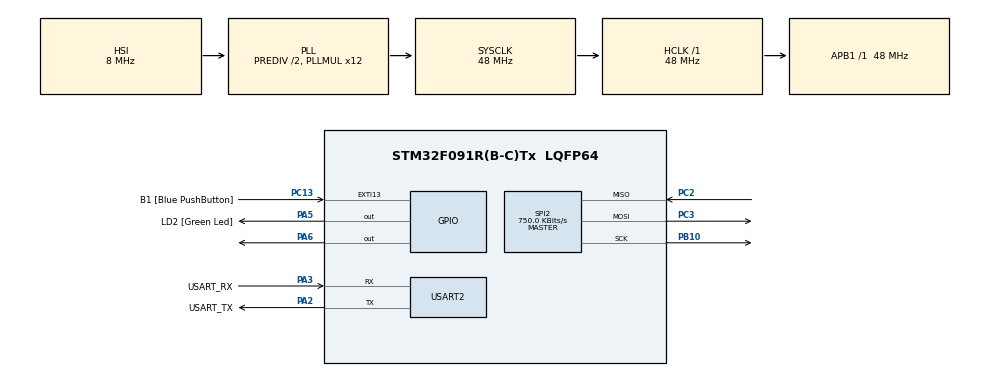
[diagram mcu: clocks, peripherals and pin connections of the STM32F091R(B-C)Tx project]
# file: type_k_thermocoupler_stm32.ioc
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Mcu.Family=STM32F0
Mcu.Name=STM32F091R(B-C)Tx
Mcu.Package=LQFP64
PA13.GPIO_Label=TMS
PA13.Mode=Serial_Wire
PA13.Signal=SYS_SWDIO
PA14.GPIO_Label=TCK
PA14.Mode=Serial_Wire
PA14.Signal=SYS_SWCLK
PA2.GPIO_Label=USART_TX
PA2.GPIO_Mode=GPIO_MODE_AF_PP
PA2.GPIO_PuPd=GPIO_NOPULL
PA2.GPIO_Speed=GPIO_SPEED_FREQ_LOW
PA2.Mode=Asynchronous
PA2.Signal=USART2_TX
PA3.GPIO_Label=USART_RX
PA3.GPIO_Mode=GPIO_MODE_AF_PP
PA3.GPIO_PuPd=GPIO_NOPULL
PA3.GPIO_Speed=GPIO_SPEED_FREQ_LOW
PA3.Mode=Asynchronous
PA3.Signal=USART2_RX
PA5.GPIO_Label=LD2 [Green Led]
PA5.GPIO_Mode=GPIO_MODE_OUTPUT_PP
PA5.GPIO_PuPd=GPIO_NOPULL
PA5.GPIO_Speed=GPIO_SPEED_FREQ_LOW
PA5.Signal=GPIO_Output
PA6.Signal=GPIO_Output
PB10.Mode=Full_Duplex_Master
PB10.Signal=SPI2_SCK
PC13.GPIO_Label=B1 [Blue PushButton]
PC13.GPIO_ModeDefaultEXTI=GPIO_MODE_IT_FALLING
PC13.Signal=GPXTI13
PC14OSC32_IN.Mode=LSE-External-Oscillator
PC14OSC32_IN.Signal=RCC_OSC32_IN
PC15OSC32_OUT.Mode=LSE-External-Oscillator
PC15OSC32_OUT.Signal=RCC_OSC32_OUT
PC2.Mode=Full_Duplex_Master
PC2.Signal=SPI2_MISO
PC3.Mode=Full_Duplex_Master
PC3.Signal=SPI2_MOSI
PF0-OSC_IN.Mode=HSE-External-Clock-Source
PF0-OSC_IN.Signal=RCC_OSC_IN
PF1-OSC_OUT.Signal=RCC_OSC_OUT
ProjectManager.HeapSize=0x200
ProjectManager.StackSize=0x400
ProjectManager.TargetToolchain=STM32CubeIDE
RCC.AHBFreq_Value=48000000
RCC.APB1Freq_Value=48000000
RCC.APB1TimFreq_Value=48000000
RCC.FLatency-AdvancedSettings=FLASH_LATENCY_1
RCC.HCLKFreq_Value=48000000
RCC.PLLDivider=RCC_PREDIV_DIV2
RCC.PLLMUL=RCC_PLL_MUL12
RCC.PREFETCH_ENABLE-AdvancedSettings=1
RCC.SYSCLKFreq_VALUE=48000000
RCC.SYSCLKSource=RCC_SYSCLKSOURCE_PLLCLK
SPI2.BaudRatePrescaler=SPI_BAUDRATEPRESCALER_64
SPI2.CalculateBaudRate=750.0 KBits/s
SPI2.DataSize=SPI_DATASIZE_16BIT
SPI2.Direction=SPI_DIRECTION_2LINES
SPI2.Mode=SPI_MODE_MASTER
SPI2.VirtualType=VM_MASTER
USART2.VirtualMode=VM_ASYNC
USART2.VirtualMode-Asynchronous=VM_ASYNC
board=NUCLEO-F091RC

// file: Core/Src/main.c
/* USER CODE BEGIN Header */
/**
  ******************************************************************************
  * @file           : main.c
  * @brief          : Main program body
  ******************************************************************************
  * @attention
  *
  * Copyright (c) 2022 STMicroelectronics.
  * All rights reserved.
  *
  * This software is licensed under terms that can be found in the LICENSE file
  * in the root directory of this software component.
  * If no LICENSE file comes with this software, it is provided AS-IS.
  *
  ******************************************************************************
  */
/* USER CODE END Header */
#include "main.h"

#include <stdio.h>
#include <string.h>
#include "max6675.h"

SPI_HandleTypeDef hspi2;
ThermoCouple sensor_th1;
UART_HandleTypeDef huart2;

void SystemClock_Config(void);
static void MX_GPIO_Init(void);
static void MX_USART2_UART_Init(void);
static void MX_SPI2_Init(void);
static void InitThermocouple1(void);

int main(void)
{

  /* MCU Configuration--------------------------------------------------------*/

  /* Reset of all peripherals, Initializes the Flash interface and the Systick. */
  HAL_Init();

  /* Configure the system clock */
  SystemClock_Config();

  /* Initialize all configured peripherals */
  MX_GPIO_Init();
  MX_USART2_UART_Init();
  MX_SPI2_Init();
  InitThermocouple1();

  /* Infinite loop */
  /* USER CODE BEGIN WHILE */
  float Th1_temp = 0;
  int intpart, fracpart;
  char txt1[11];
  while (1)
  {
	  ReadThermoCouple(&sensor_th1);
	  if(sensor_th1.connected) {
		  Th1_temp = sensor_th1.Thx_celcius;
		  intpart = (int)Th1_temp;
		  fracpart = (int)((Th1_temp - intpart)* 100);
		  snprintf(txt1,11,"%3d.%02d",intpart,fracpart);

	  HAL_Delay(100);
	  }
    /* USER CODE END WHILE */

  }
}

void InitThermocouple1(void)
{
	  sensor_th1.Thx_CS_Pin = Th1_CS_Pin;			// CS Pin
	  sensor_th1.Thx_CS_Port = Th1_CS_GPIO_Port;	// CS GPIO PORT
	  sensor_th1.hspi = &hspi2;						// SPI2
}
void SystemClock_Config(void)
{
  RCC_OscInitTypeDef RCC_OscInitStruct = {0};
  RCC_ClkInitTypeDef RCC_ClkInitStruct = {0};
  RCC_PeriphCLKInitTypeDef PeriphClkInit = {0};

  /** Initializes the RCC Oscillators according to the specified parameters
  * in the RCC_OscInitTypeDef structure.
  */
  RCC_OscInitStruct.OscillatorType = RCC_OSCILLATORTYPE_HSI;
  RCC_OscInitStruct.HSIState = RCC_HSI_ON;
  RCC_OscInitStruct.HSICalibrationValue = RCC_HSICALIBRATION_DEFAULT;
  RCC_OscInitStruct.PLL.PLLState = RCC_PLL_ON;
  RCC_OscInitStruct.PLL.PLLSource = RCC_PLLSOURCE_HSI;
  RCC_OscInitStruct.PLL.PLLMUL = RCC_PLL_MUL12;
  RCC_OscInitStruct.PLL.PREDIV = RCC_PREDIV_DIV2;
  if (HAL_RCC_OscConfig(&RCC_OscInitStruct) != HAL_OK)
  {
    Error_Handler();
  }
  /** Initializes the CPU, AHB and APB buses clocks
  */
  RCC_ClkInitStruct.ClockType = RCC_CLOCKTYPE_HCLK|RCC_CLOCKTYPE_SYSCLK
                              |RCC_CLOCKTYPE_PCLK1;
  RCC_ClkInitStruct.SYSCLKSource = RCC_SYSCLKSOURCE_PLLCLK;
  RCC_ClkInitStruct.AHBCLKDivider = RCC_SYSCLK_DIV1;
  RCC_ClkInitStruct.APB1CLKDivider = RCC_HCLK_DIV1;

  if (HAL_RCC_ClockConfig(&RCC_ClkInitStruct, FLASH_LATENCY_1) != HAL_OK)
  {
    Error_Handler();
  }
  PeriphClkInit.PeriphClockSelection = RCC_PERIPHCLK_USART2;
  PeriphClkInit.Usart2ClockSelection = RCC_USART2CLKSOURCE_PCLK1;
  if (HAL_RCCEx_PeriphCLKConfig(&PeriphClkInit) != HAL_OK)
  {
    Error_Handler();
  }
}

static void MX_SPI2_Init(void)
{

  /* SPI2 parameter configuration*/
  hspi2.Instance = SPI2;
  hspi2.Init.Mode = SPI_MODE_MASTER;
  hspi2.Init.Direction = SPI_DIRECTION_2LINES;
  hspi2.Init.DataSize = SPI_DATASIZE_16BIT;
  hspi2.Init.CLKPolarity = SPI_POLARITY_LOW;
  hspi2.Init.CLKPhase = SPI_PHASE_1EDGE;
  hspi2.Init.NSS = SPI_NSS_SOFT;
  hspi2.Init.BaudRatePrescaler = SPI_BAUDRATEPRESCALER_64;
  hspi2.Init.FirstBit = SPI_FIRSTBIT_MSB;
  hspi2.Init.TIMode = SPI_TIMODE_DISABLE;
  hspi2.Init.CRCCalculation = SPI_CRCCALCULATION_DISABLE;
  hspi2.Init.CRCPolynomial = 7;
  hspi2.Init.CRCLength = SPI_CRC_LENGTH_DATASIZE;
  hspi2.Init.NSSPMode = SPI_NSS_PULSE_ENABLE;
  if (HAL_SPI_Init(&hspi2) != HAL_OK)
  {
    Error_Handler();
  }

}

static void MX_USART2_UART_Init(void)
{

  huart2.Instance = USART2;
  huart2.Init.BaudRate = 115200;
  huart2.Init.WordLength = UART_WORDLENGTH_8B;
  huart2.Init.StopBits = UART_STOPBITS_1;
  huart2.Init.Parity = UART_PARITY_NONE;
  huart2.Init.Mode = UART_MODE_TX_RX;
  huart2.Init.HwFlowCtl = UART_HWCONTROL_NONE;
  huart2.Init.OverSampling = UART_OVERSAMPLING_16;
  huart2.Init.OneBitSampling = UART_ONE_BIT_SAMPLE_DISABLE;
  huart2.AdvancedInit.AdvFeatureInit = UART_ADVFEATURE_NO_INIT;
  if (HAL_UART_Init(&huart2) != HAL_OK)
  {
    Error_Handler();
  }

}

static void MX_GPIO_Init(void)
{
  GPIO_InitTypeDef GPIO_InitStruct = {0};

  /* GPIO Ports Clock Enable */
  __HAL_RCC_GPIOC_CLK_ENABLE();
  __HAL_RCC_GPIOF_CLK_ENABLE();
  __HAL_RCC_GPIOA_CLK_ENABLE();
  __HAL_RCC_GPIOB_CLK_ENABLE();

  /*Configure GPIO pin Output Level */
  HAL_GPIO_WritePin(GPIOA, GPIO_PIN_5, GPIO_PIN_RESET);

  /*Configure GPIO pin : PC13 */
  GPIO_InitStruct.Pin = GPIO_PIN_13;
  GPIO_InitStruct.Mode = GPIO_MODE_IT_FALLING;
  GPIO_InitStruct.Pull = GPIO_NOPULL;
  HAL_GPIO_Init(GPIOC, &GPIO_InitStruct);

  /*Configure GPIO pin : PA5 */
  GPIO_InitStruct.Pin = GPIO_PIN_5;
  GPIO_InitStruct.Mode = GPIO_MODE_OUTPUT_PP;
  GPIO_InitStruct.Pull = GPIO_NOPULL;
  GPIO_InitStruct.Speed = GPIO_SPEED_FREQ_LOW;
  HAL_GPIO_Init(GPIOA, &GPIO_InitStruct);

}

void Error_Handler(void)
{
  __disable_irq();
  while (1)
  {
  }
}
